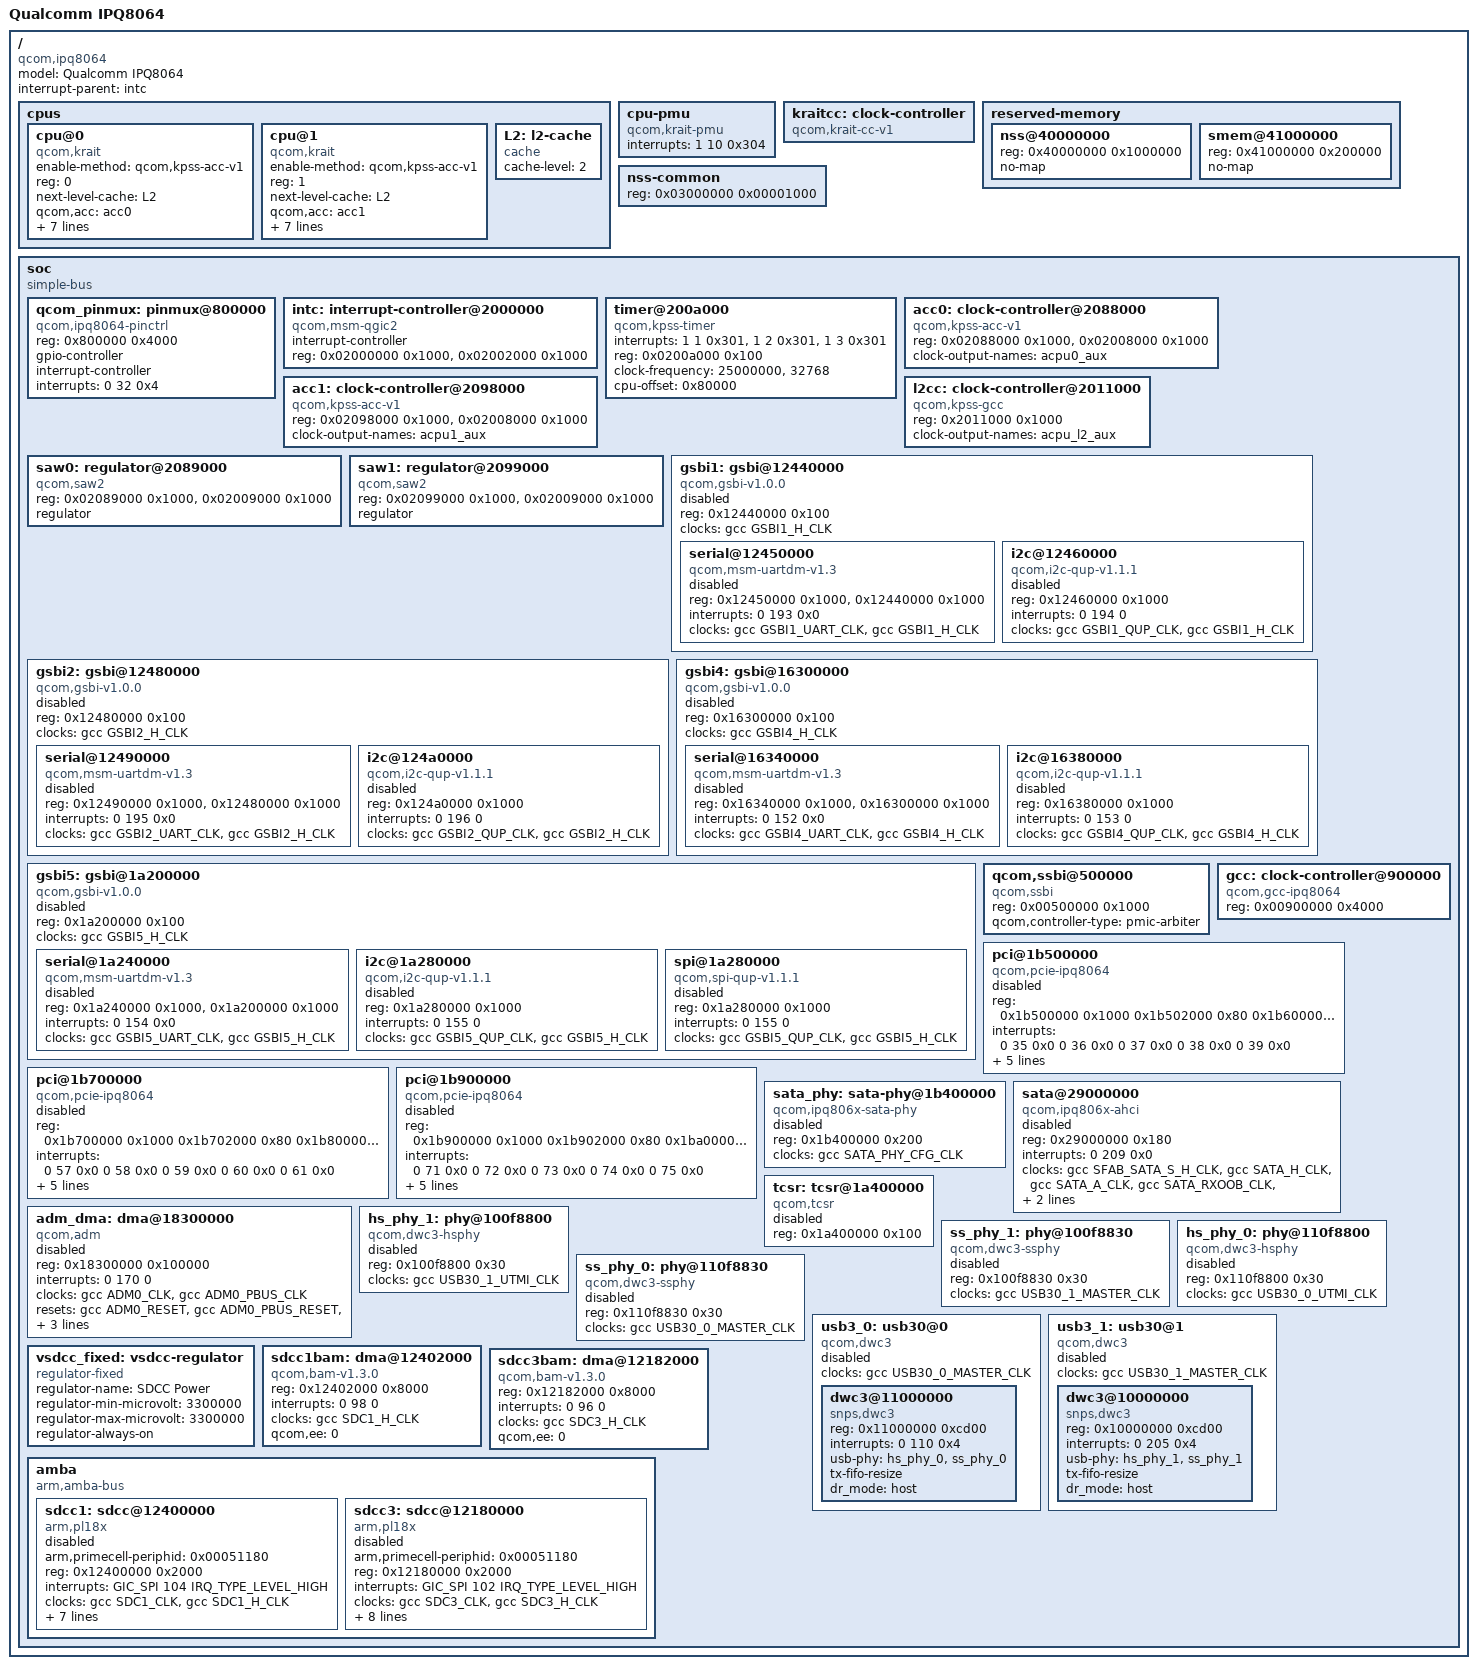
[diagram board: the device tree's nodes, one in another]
/dts-v1/;

#include "skeleton.dtsi"
#include <dt-bindings/clock/qcom,gcc-ipq806x.h>
#include <dt-bindings/reset/qcom,gcc-ipq806x.h>
#include <dt-bindings/soc/qcom,gsbi.h>
#include <dt-bindings/soc/qcom,tcsr.h>
#include <dt-bindings/interrupt-controller/arm-gic.h>

/ {
	model = "Qualcomm IPQ8064";
	compatible = "qcom,ipq8064";
	interrupt-parent = <&intc>;

	cpus {
		#address-cells = <1>;
		#size-cells = <0>;

		cpu@0 {
			compatible = "qcom,krait";
			enable-method = "qcom,kpss-acc-v1";
			device_type = "cpu";
			reg = <0>;
			next-level-cache = <&L2>;
			qcom,acc = <&acc0>;
			qcom,saw = <&saw0>;
			clocks = <&kraitcc 0>;
			clock-names = "cpu";
			operating-points = <
				/* kHz    ignored */
				1400000 1000000
				1200000 1000000
				1000000 1000000
				 800000 1000000
				 600000 1000000
				 384000 1000000
			>;
			clock-latency = <100000>;

			cooling-min-state = <0>;
			cooling-max-state = <10>;
			#cooling-cells = <2>;
		};

		cpu@1 {
			compatible = "qcom,krait";
			enable-method = "qcom,kpss-acc-v1";
			device_type = "cpu";
			reg = <1>;
			next-level-cache = <&L2>;
			qcom,acc = <&acc1>;
			qcom,saw = <&saw1>;
			clocks = <&kraitcc 1>;
			clock-names = "cpu";
			operating-points = <
				/* kHz    ignored */
				1400000 1000000
				1200000 1000000
				1000000 1000000
				 800000 1000000
				 600000 1000000
				 384000 1000000
			>;
			clock-latency = <100000>;

			cooling-min-state = <0>;
			cooling-max-state = <10>;
			#cooling-cells = <2>;
		};

		L2: l2-cache {
			compatible = "cache";
			cache-level = <2>;
		};
	};

	cpu-pmu {
		compatible = "qcom,krait-pmu";
		interrupts = <1 10 0x304>;
	};

	kraitcc: clock-controller {
		compatible = "qcom,krait-cc-v1";
		#clock-cells = <1>;
	};

	reserved-memory {
		#address-cells = <1>;
		#size-cells = <1>;
		ranges;

		nss@40000000 {
			reg = <0x40000000 0x1000000>;
			no-map;
		};

		smem@41000000 {
			reg = <0x41000000 0x200000>;
			no-map;
		};
	};

	nss-common {
		reg = <0x03000000 0x00001000>;
		reg-names = "nss_fpb_base";
	};

	soc: soc {
		#address-cells = <1>;
		#size-cells = <1>;
		ranges;
		compatible = "simple-bus";

		qcom_pinmux: pinmux@800000 {
			compatible = "qcom,ipq8064-pinctrl";
			reg = <0x800000 0x4000>;

			gpio-controller;
			#gpio-cells = <2>;
			interrupt-controller;
			#interrupt-cells = <2>;
			interrupts = <0 32 0x4>;
		};

		intc: interrupt-controller@2000000 {
			compatible = "qcom,msm-qgic2";
			interrupt-controller;
			#interrupt-cells = <3>;
			reg = <0x02000000 0x1000>,
			      <0x02002000 0x1000>;
		};

		timer@200a000 {
			compatible = "qcom,kpss-timer", "qcom,msm-timer";
			interrupts = <1 1 0x301>,
				     <1 2 0x301>,
				     <1 3 0x301>;
			reg = <0x0200a000 0x100>;
			clock-frequency = <25000000>,
					  <32768>;
			cpu-offset = <0x80000>;
		};

		acc0: clock-controller@2088000 {
			compatible = "qcom,kpss-acc-v1";
			reg = <0x02088000 0x1000>, <0x02008000 0x1000>;
			clock-output-names = "acpu0_aux";
		};

		acc1: clock-controller@2098000 {
			compatible = "qcom,kpss-acc-v1";
			reg = <0x02098000 0x1000>, <0x02008000 0x1000>;
			clock-output-names = "acpu1_aux";
		};

		l2cc: clock-controller@2011000 {
			compatible = "qcom,kpss-gcc";
			reg = <0x2011000 0x1000>;
			clock-output-names = "acpu_l2_aux";
		};

		saw0: regulator@2089000 {
			compatible = "qcom,saw2";
			reg = <0x02089000 0x1000>, <0x02009000 0x1000>;
			regulator;
		};

		saw1: regulator@2099000 {
			compatible = "qcom,saw2";
			reg = <0x02099000 0x1000>, <0x02009000 0x1000>;
			regulator;
		};

		gsbi1: gsbi@12440000 {
			compatible = "qcom,gsbi-v1.0.0";
			reg = <0x12440000 0x100>;
			clocks = <&gcc GSBI1_H_CLK>;
			clock-names = "iface";
			#address-cells = <1>;
			#size-cells = <1>;
			ranges;
			status = "disabled";

			serial@12450000 {
				compatible = "qcom,msm-uartdm-v1.3", "qcom,msm-uartdm";
				reg = <0x12450000 0x1000>,
				      <0x12440000 0x1000>;
				interrupts = <0 193 0x0>;
				clocks = <&gcc GSBI1_UART_CLK>, <&gcc GSBI1_H_CLK>;
				clock-names = "core", "iface";
				status = "disabled";
			};

			i2c@12460000 {
				compatible = "qcom,i2c-qup-v1.1.1";
				reg = <0x12460000 0x1000>;
				interrupts = <0 194 0>;

				clocks = <&gcc GSBI1_QUP_CLK>, <&gcc GSBI1_H_CLK>;
				clock-names = "core", "iface";
				status = "disabled";

				#address-cells = <1>;
				#size-cells = <0>;
			};

		};

		gsbi2: gsbi@12480000 {
			compatible = "qcom,gsbi-v1.0.0";
			reg = <0x12480000 0x100>;
			clocks = <&gcc GSBI2_H_CLK>;
			clock-names = "iface";
			#address-cells = <1>;
			#size-cells = <1>;
			ranges;
			status = "disabled";

			serial@12490000 {
				compatible = "qcom,msm-uartdm-v1.3", "qcom,msm-uartdm";
				reg = <0x12490000 0x1000>,
				      <0x12480000 0x1000>;
				interrupts = <0 195 0x0>;
				clocks = <&gcc GSBI2_UART_CLK>, <&gcc GSBI2_H_CLK>;
				clock-names = "core", "iface";
				status = "disabled";
			};

			i2c@124a0000 {
				compatible = "qcom,i2c-qup-v1.1.1";
				reg = <0x124a0000 0x1000>;
				interrupts = <0 196 0>;

				clocks = <&gcc GSBI2_QUP_CLK>, <&gcc GSBI2_H_CLK>;
				clock-names = "core", "iface";
				status = "disabled";

				#address-cells = <1>;
				#size-cells = <0>;
			};

		};

		gsbi4: gsbi@16300000 {
			compatible = "qcom,gsbi-v1.0.0";
			reg = <0x16300000 0x100>;
			clocks = <&gcc GSBI4_H_CLK>;
			clock-names = "iface";
			#address-cells = <1>;
			#size-cells = <1>;
			ranges;
			status = "disabled";

			serial@16340000 {
				compatible = "qcom,msm-uartdm-v1.3", "qcom,msm-uartdm";
				reg = <0x16340000 0x1000>,
				      <0x16300000 0x1000>;
				interrupts = <0 152 0x0>;
				clocks = <&gcc GSBI4_UART_CLK>, <&gcc GSBI4_H_CLK>;
				clock-names = "core", "iface";
				status = "disabled";
			};

			i2c@16380000 {
				compatible = "qcom,i2c-qup-v1.1.1";
				reg = <0x16380000 0x1000>;
				interrupts = <0 153 0>;

				clocks = <&gcc GSBI4_QUP_CLK>, <&gcc GSBI4_H_CLK>;
				clock-names = "core", "iface";
				status = "disabled";

				#address-cells = <1>;
				#size-cells = <0>;
			};
		};

		gsbi5: gsbi@1a200000 {
			compatible = "qcom,gsbi-v1.0.0";
			reg = <0x1a200000 0x100>;
			clocks = <&gcc GSBI5_H_CLK>;
			clock-names = "iface";
			#address-cells = <1>;
			#size-cells = <1>;
			ranges;
			status = "disabled";

			serial@1a240000 {
				compatible = "qcom,msm-uartdm-v1.3", "qcom,msm-uartdm";
				reg = <0x1a240000 0x1000>,
				      <0x1a200000 0x1000>;
				interrupts = <0 154 0x0>;
				clocks = <&gcc GSBI5_UART_CLK>, <&gcc GSBI5_H_CLK>;
				clock-names = "core", "iface";
				status = "disabled";
			};

			i2c@1a280000 {
				compatible = "qcom,i2c-qup-v1.1.1";
				reg = <0x1a280000 0x1000>;
				interrupts = <0 155 0>;

				clocks = <&gcc GSBI5_QUP_CLK>, <&gcc GSBI5_H_CLK>;
				clock-names = "core", "iface";
				status = "disabled";

				#address-cells = <1>;
				#size-cells = <0>;
			};

			spi@1a280000 {
				compatible = "qcom,spi-qup-v1.1.1";
				reg = <0x1a280000 0x1000>;
				interrupts = <0 155 0>;

				clocks = <&gcc GSBI5_QUP_CLK>, <&gcc GSBI5_H_CLK>;
				clock-names = "core", "iface";
				status = "disabled";

				#address-cells = <1>;
				#size-cells = <0>;
			};
		};

		qcom,ssbi@500000 {
			compatible = "qcom,ssbi";
			reg = <0x00500000 0x1000>;
			qcom,controller-type = "pmic-arbiter";
		};

		gcc: clock-controller@900000 {
			compatible = "qcom,gcc-ipq8064";
			reg = <0x00900000 0x4000>;
			#clock-cells = <1>;
			#reset-cells = <1>;
		};

		pci@1b500000 {
			compatible = "qcom,pcie-ipq8064";
			reg = <0x1b500000 0x1000
			       0x1b502000 0x80
			       0x1b600000 0x100
				>;
			reg-names = "base", "elbi", "parf";

			#address-cells = <3>;
			#size-cells = <2>;
			device_type = "pci";
			interrupts = <0 35 0x0
				      0 36 0x0
				      0 37 0x0
				      0 38 0x0
				      0 39 0x0>;
			resets = <&gcc PCIE_ACLK_RESET>,
				 <&gcc PCIE_HCLK_RESET>,
				 <&gcc PCIE_POR_RESET>,
				 <&gcc PCIE_PCI_RESET>,
				 <&gcc PCIE_PHY_RESET>;
			reset-names = "axi", "ahb", "por", "pci", "phy";

			clocks = <&gcc PCIE_A_CLK>,
				 <&gcc PCIE_H_CLK>,
				 <&gcc PCIE_PHY_CLK>;
			clock-names = "core", "iface", "phy";
			status = "disabled";
		};

		pci@1b700000 {
			compatible = "qcom,pcie-ipq8064";
			reg = <0x1b700000 0x1000
			       0x1b702000 0x80
			       0x1b800000 0x100
				>;
			reg-names = "base", "elbi", "parf";

			#address-cells = <3>;
			#size-cells = <2>;
			device_type = "pci";

			interrupts = <0 57 0x0
				      0 58 0x0
				      0 59 0x0
				      0 60 0x0
				      0 61 0x0>;
			resets = <&gcc PCIE_1_ACLK_RESET>,
				 <&gcc PCIE_1_HCLK_RESET>,
				 <&gcc PCIE_1_POR_RESET>,
				 <&gcc PCIE_1_PCI_RESET>,
				 <&gcc PCIE_1_PHY_RESET>;
			reset-names = "axi", "ahb", "por", "pci", "phy";

			clocks = <&gcc PCIE_1_A_CLK>,
				 <&gcc PCIE_1_H_CLK>,
				 <&gcc PCIE_1_PHY_CLK>;
			clock-names = "core", "iface", "phy";
			status = "disabled";
		};

		pci@1b900000 {
			compatible = "qcom,pcie-ipq8064";
			reg = <0x1b900000 0x1000
			       0x1b902000 0x80
			       0x1ba00000 0x100
				>;
			reg-names = "base", "elbi", "parf";

			#address-cells = <3>;
			#size-cells = <2>;
			device_type = "pci";

			interrupts = <0 71 0x0
				      0 72 0x0
				      0 73 0x0
				      0 74 0x0
				      0 75 0x0>;
			resets = <&gcc PCIE_2_ACLK_RESET>,
				 <&gcc PCIE_2_HCLK_RESET>,
				 <&gcc PCIE_2_POR_RESET>,
				 <&gcc PCIE_2_PCI_RESET>,
				 <&gcc PCIE_2_PHY_RESET>;
			reset-names = "axi", "ahb", "por", "pci", "phy";

			clocks = <&gcc PCIE_2_A_CLK>,
				 <&gcc PCIE_2_H_CLK>,
				 <&gcc PCIE_2_PHY_CLK>;
			clock-names = "core", "iface", "phy";
			status = "disabled";
		};

		sata_phy: sata-phy@1b400000 {
			compatible = "qcom,ipq806x-sata-phy";
			reg = <0x1b400000 0x200>;

			clocks = <&gcc SATA_PHY_CFG_CLK>;
			clock-names = "cfg";

			#phy-cells = <0>;
			status = "disabled";
		};

		sata@29000000 {
			compatible = "qcom,ipq806x-ahci", "qcom,msm-ahci";
			reg = <0x29000000 0x180>;

			interrupts = <0 209 0x0>;

			clocks = <&gcc SFAB_SATA_S_H_CLK>,
				 <&gcc SATA_H_CLK>,
				 <&gcc SATA_A_CLK>,
				 <&gcc SATA_RXOOB_CLK>,
				 <&gcc SATA_PMALIVE_CLK>;
			clock-names = "slave_face", "iface", "core",
					"rxoob", "pmalive";

			phys = <&sata_phy>;
			phy-names = "sata-phy";
			status = "disabled";
		};

		adm_dma: dma@18300000 {
			compatible = "qcom,adm";
			reg = <0x18300000 0x100000>;
			interrupts = <0 170 0>;
			#dma-cells = <2>;

			clocks = <&gcc ADM0_CLK>, <&gcc ADM0_PBUS_CLK>;
			clock-names = "core", "iface";

			resets = <&gcc ADM0_RESET>,
				<&gcc ADM0_PBUS_RESET>,
				<&gcc ADM0_C0_RESET>,
				<&gcc ADM0_C1_RESET>,
				<&gcc ADM0_C2_RESET>;
			reset-names = "clk", "pbus", "c0", "c1", "c2";
			qcom,ee = <0>;

			status = "disabled";

		};

		tcsr: tcsr@1a400000 {
			compatible = "qcom,tcsr";
			reg = <0x1a400000 0x100>;

			status = "disabled";
		};

		hs_phy_1: phy@100f8800 {
			compatible = "qcom,dwc3-hsphy";
			reg = <0x100f8800 0x30>;
			clocks = <&gcc USB30_1_UTMI_CLK>;
			clock-names = "utmi";

			status = "disabled";
		};

		ss_phy_1: phy@100f8830 {
			compatible = "qcom,dwc3-ssphy";
			reg = <0x100f8830 0x30>;

			clocks = <&gcc USB30_1_MASTER_CLK>;
			clock-names = "ref";

			status = "disabled";
		};

		hs_phy_0: phy@110f8800 {
			compatible = "qcom,dwc3-hsphy";
			reg = <0x110f8800 0x30>;
			clocks = <&gcc USB30_0_UTMI_CLK>;
			clock-names = "utmi";

			status = "disabled";
		};

		ss_phy_0: phy@110f8830 {
			compatible = "qcom,dwc3-ssphy";
			reg = <0x110f8830 0x30>;

			clocks = <&gcc USB30_0_MASTER_CLK>;
			clock-names = "ref";

			status = "disabled";
		};

		usb3_0: usb30@0 {
			compatible = "qcom,dwc3";
			#address-cells = <1>;
			#size-cells = <1>;
			clocks = <&gcc USB30_0_MASTER_CLK>;
			clock-names = "core";

			ranges;

			status = "disabled";

			dwc3@11000000 {
				compatible = "snps,dwc3";
				reg = <0x11000000 0xcd00>;
				interrupts = <0 110 0x4>;
				usb-phy = <&hs_phy_0>, <&ss_phy_0>;
				phy-names = "usb2-phy", "usb3-phy";
				tx-fifo-resize;
				dr_mode = "host";
			};
		};

		usb3_1: usb30@1 {
			compatible = "qcom,dwc3";
			#address-cells = <1>;
			#size-cells = <1>;
			clocks = <&gcc USB30_1_MASTER_CLK>;
			clock-names = "core";

			ranges;

			status = "disabled";

			dwc3@10000000 {
				compatible = "snps,dwc3";
				reg = <0x10000000 0xcd00>;
				interrupts = <0 205 0x4>;
				usb-phy = <&hs_phy_1>, <&ss_phy_1>;
				phy-names = "usb2-phy", "usb3-phy";
				tx-fifo-resize;
				dr_mode = "host";
			};
		};

		/* Temporary fixed regulator */
		vsdcc_fixed: vsdcc-regulator {
			compatible = "regulator-fixed";
			regulator-name = "SDCC Power";
			regulator-min-microvolt = <3300000>;
			regulator-max-microvolt = <3300000>;
			regulator-always-on;
		};

		sdcc1bam:dma@12402000 {
			compatible = "qcom,bam-v1.3.0";
			reg = <0x12402000 0x8000>;
			interrupts = <0 98 0>;
			clocks = <&gcc SDC1_H_CLK>;
			clock-names = "bam_clk";
			#dma-cells = <1>;
			qcom,ee = <0>;
                };

		sdcc3bam:dma@12182000 {
			compatible = "qcom,bam-v1.3.0";
			reg = <0x12182000 0x8000>;
			interrupts = <0 96 0>;
			clocks = <&gcc SDC3_H_CLK>;
			clock-names = "bam_clk";
			#dma-cells = <1>;
			qcom,ee = <0>;
		};

		amba {
			compatible = "arm,amba-bus";
			#address-cells = <1>;
			#size-cells = <1>;
			ranges;
			sdcc1: sdcc@12400000 {
				status          = "disabled";
				compatible      = "arm,pl18x", "arm,primecell";
				arm,primecell-periphid = <0x00051180>;
				reg             = <0x12400000 0x2000>;
				interrupts      = <GIC_SPI 104 IRQ_TYPE_LEVEL_HIGH>;
				interrupt-names = "cmd_irq";
				clocks          = <&gcc SDC1_CLK>, <&gcc SDC1_H_CLK>;
				clock-names     = "mclk", "apb_pclk";
				bus-width       = <8>;
				max-frequency   = <48000000>;
				non-removable;
				cap-sd-highspeed;
				cap-mmc-highspeed;
				vmmc-supply = <&vsdcc_fixed>;
				dmas = <&sdcc1bam 2>, <&sdcc1bam 1>;
				dma-names = "tx", "rx";
			};

			sdcc3: sdcc@12180000 {
				compatible      = "arm,pl18x", "arm,primecell";
				arm,primecell-periphid = <0x00051180>;
				status          = "disabled";
				reg             = <0x12180000 0x2000>;
				interrupts      = <GIC_SPI 102 IRQ_TYPE_LEVEL_HIGH>;
				interrupt-names = "cmd_irq";
				clocks          = <&gcc SDC3_CLK>, <&gcc SDC3_H_CLK>;
				clock-names     = "mclk", "apb_pclk";
				bus-width       = <8>;
				cap-sd-highspeed;
				cap-mmc-highspeed;
				max-frequency   = <192000000>;
				#mmc-ddr-1_8v;
				sd-uhs-sdr50;
				vmmc-supply = <&vsdcc_fixed>;
				dmas = <&sdcc3bam 2>, <&sdcc3bam 1>;
				dma-names = "tx", "rx";
			};
		};
	};
};
